# max32572 register map
Vendor: Maxim-Integrated; Series: ARMCM4; File version: 1.0
CPU: CM4 r2p1, little endian, MPU, FPU, 3 interrupt priority bits
Registers are 32-bit, read-write, reset 0x0 unless marked. A register's access mark holds for its fields unless they carry their own. Offsets are from the block's base; [hi:lo] are bit positions.

## FCR — Function Control Register.
Base 0x40000800
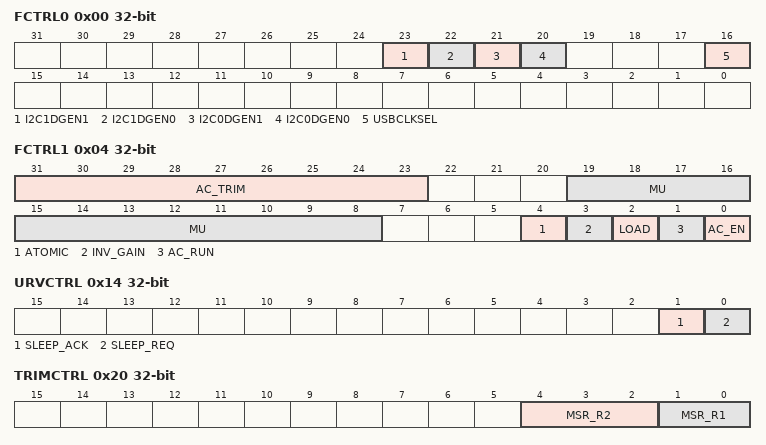
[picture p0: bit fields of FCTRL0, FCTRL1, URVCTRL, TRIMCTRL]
0x00 FCTRL0 — Register 0.
  [23] I2C1DGEN1 — I2C1 SCL Glitch Filter Enable.
    0=dis (Filter disabled.); 1=en (Filter enabled.)
  [22] I2C1DGEN0 — I2C1 SDA Glitch Filter Enable.
    0=dis (Filter disabled.); 1=en (Filter enabled.)
  [21] I2C0DGEN1 — I2C0 SCL Glitch Filter Enable.
    0=dis (Filter disabled.); 1=en (Filter enabled.)
  [20] I2C0DGEN0 — I2C0 SDA Glitch Filter Enable.
    0=dis (Filter disabled.); 1=en (Filter enabled.)
  [16] USBCLKSEL — USB External Core Clock Select.
    0=sys (Generated clock from system clock.); 1=dig (Digital clock from a GPIO.)
0x04 FCTRL1 — Register 1.
  [31:23] AC_TRIM — 150MHz HFIO Auto Calibration Trim
  [19:8] MU — MU value.
  [4] ATOMIC — Atomic mode.
    0=not (Not Running.); 1=run (Running.)
  [3] INV_GAIN — Invert Gain.
    0=not (Not Running.); 1=run (Running.)
  [2] LOAD — Load Trim.
  [1] AC_RUN — Autocalibration Run.
    0=not (Not Running.); 1=run (Running.)
  [0] AC_EN — Auto-calibration Enable.
    0=dis (Disabled.); 1=en (Enabled.)
0x0C FCTRL3 — Register 3.
  [7:0] DONECNT — Auto-calibration Done Counter Setting.
0x10 URVBOOTADDR — Register 4.
  [31:0] BOOTADDR — RISCV Boot Address.
0x14 URVCTRL — Register 5.
  [1] SLEEP_ACK — Acknowledgement of Sleep Request for RISCV.
  [0] SLEEP_REQ — Sleep Request to RISCV.
0x1C GP — General Purpose Register.
  [31:0] GP — General Purpose.
0x20 TRIMCTRL — MSR ADC Trim Register.
  [4:2] MSR_R2
    0=OPEN (Open drain.); 4=3K (3kOhm); 5=6K (6kOhm); 6=12K (12kOhm); 7=24K (24kOhm)
  [1:0] MSR_R1
    0=0K (0kOhm); 1=1P2K (1.2kOhm); 2=2P4K (2.4kOhm); 3=4P8K (4.8kOhm)
0x24 ERFOKS — ERFO Kick Start Register.
  [15:0] CTRL — Kick Start Control.

## TRIMSIR — Trim System Initilazation Registers
Base 0x40005400
0x08 BBSIR2 ro — System Init. Configuration Register 2.
0x0C BBSIR3 ro — System Init. Configuration Register 3.

## MCR — Misc Control.
Base 0x40006C00
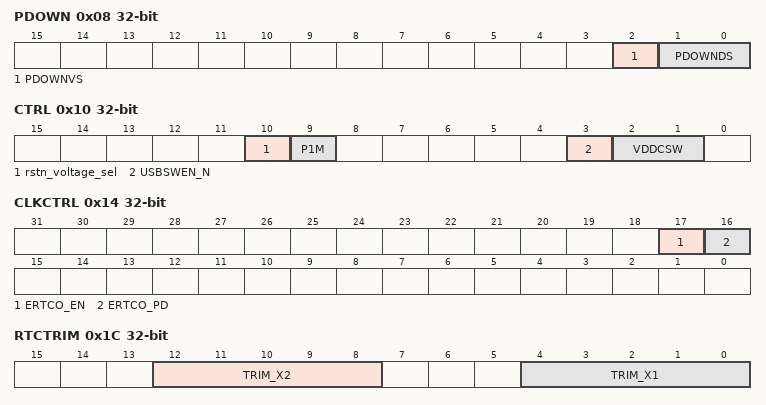
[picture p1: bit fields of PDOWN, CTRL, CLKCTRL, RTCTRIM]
0x08 PDOWN — PDOWN Drive Strength
  [2] PDOWNVS — PDOWN Voltage Select
  [1:0] PDOWNDS — PDOWN Drive Strength
0x10 CTRL — Misc Power State Control Register
  [10] rstn_voltage_sel — Error! Description not Found!
  [9] P1M — Enable the Reset Pad Pull Up Resistors
    0=1m (1MOhm Pullup); 1=25k (25kOhm Pullup.)
  [3] USBSWEN_N — USB Switch Control
    1=off (USB SW off in LP modes); 0=on (USB SW On)
  [2:1] VDDCSW — Controls switching of VCORE
0x14 CLKCTRL — Clock Control Register.
  [17] ERTCO_EN — 32kHz Crystal Oscillator Enable.
  [16] ERTCO_PD — 32kHz Crystal Oscillator Power Down.
0x18 RST — Reset Register.
  [0] RTC — Real Time Cock Reset.
0x1C RTCTRIM
  [12:8] TRIM_X2 — RTC TRIM X2
  [4:0] TRIM_X1 — RTC Trim X1
0x60 LDOCTRL — LDO Control Register.
  [0] 0P9V_EN — LDO 0.9V Enable.
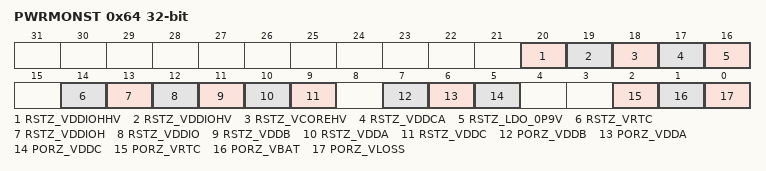
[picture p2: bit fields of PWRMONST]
0x64 PWRMONST — Power Monitor Statuses Register.
  [20] RSTZ_VDDIOHHV — Non-sticky bit indicating high voltage reset condition on VDDIOH supply.
  [19] RSTZ_VDDIOHV — Non-sticky bit indicating high voltage reset condition on VDDIO supply.
  [18] RSTZ_VCOREHV — Non-sticky bit indicating high voltage reset condition on VCORE supply.
  [17] RSTZ_VDDCA — Non-sticky bit indicating reset condition on VCORE in Analog supply.
  [16] RSTZ_LDO_0P9V — Non-sticky bit indicating reset condition on 0.9V USB supply.
  [14] RSTZ_VRTC — Sticky bit indicating reset condition on RTC.
  [13] RSTZ_VDDIOH — Sticky bit indicating reset condition on VDDIOH.
  [12] RSTZ_VDDIO — Sticky bit indicating reset condition on VDDIO.
  [11] RSTZ_VDDB — Sticky bit indicating reset condition on VDDB.
  [10] RSTZ_VDDA — Sticky bit indicating reset condition on VDDA.
  [9] RSTZ_VDDC — Sticky bit indicating reset condition on VCORE.
  [7] PORZ_VDDB — Sticky bit indicating power on status of VDDB.
  [6] PORZ_VDDA — Sticky bit indicating power on status of VDDA.
  [5] PORZ_VDDC — Sticky bit indicating power on status of VCORE.
  [2] PORZ_VRTC — Sticky bit indicating power on status of the RTC.
  [1] PORZ_VBAT — Sticky bit indicating power on status of the battery.
  [0] PORZ_VLOSS — Sticky bit indicating power on status of core power domains.
